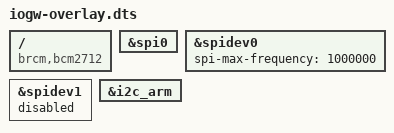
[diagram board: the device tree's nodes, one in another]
// SPDX-License-Identifier: GPL-2.0
// IO Gateway: SPI0 (MCP3008) and I2C1 (SHT31). Enable with dtoverlay=iogw.
// Structure and approach follow the stock raspberrypi/linux overlays
// spi0-1cs and i2c1-pi5 (arch/arm64/boot/dts/overlays/).

/dts-v1/;
/plugin/;

/ {
	compatible = "brcm,bcm2712";

	fragment@0 {
		target = <&spi0>;
		__overlay__ {
			status = "okay";
		};
	};

	fragment@1 {
		target = <&spidev0>;
		__overlay__ {
			spi-max-frequency = <1000000>;	/* MCP3008 at 3.3 V */
		};
	};

	fragment@2 {
		target = <&spidev1>;
		__overlay__ {
			status = "disabled";
		};
	};

	fragment@3 {
		target = <&i2c_arm>;
		__overlay__ {
			status = "okay";
		};
	};
};
